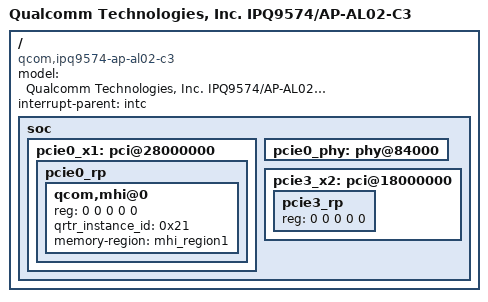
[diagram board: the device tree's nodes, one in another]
// SPDX-License-Identifier: (GPL-2.0+ OR BSD-3-Clause)
/*
 * IPQ9574 AL02-C3 board device tree source
 *
 * Copyright (c) 2020-2021 The Linux Foundation. All rights reserved.
 */

/dts-v1/;

#include "ipq9574-al02-c2.dts"

/ {
	#address-cells = <0x2>;
	#size-cells = <0x2>;
	model = "Qualcomm Technologies, Inc. IPQ9574/AP-AL02-C3";
	compatible = "qcom,ipq9574-ap-al02-c3", "qcom,ipq9574-al02", "qcom,ipq9574";
	interrupt-parent = <&intc>;

	soc {
		pcie0_x1: pci@28000000 {
			status = "ok";
			pcie0_rp {
				qcom,mhi@0 {
					reg = <0 0 0 0 0>;
					qrtr_instance_id = <0x21>;
					memory-region = <&mhi_region1>;
				};
			};

		};

		pcie0_phy: phy@84000 {
			status = "ok";
		};

		pcie3_x2: pci@18000000 {
			/* delete pcie3_rp node to remove QCN9000 related entries
			 * and add it again only with reg as like other PCIE */
			/delete-node/ pcie3_rp;
			pcie3_rp {
				reg = <0 0 0 0 0>;
			};
		};
	};
};
